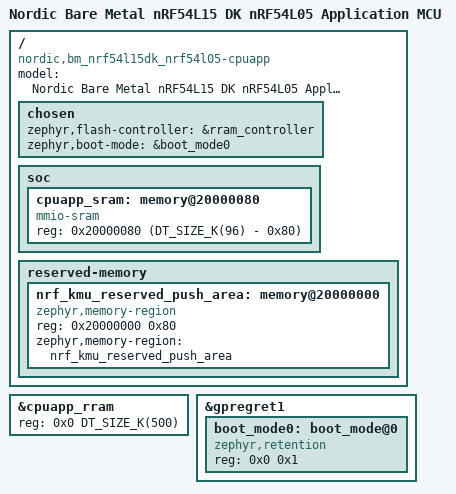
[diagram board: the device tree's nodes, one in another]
/*
 * Copyright (c) 2025 Nordic Semiconductor ASA
 *
 * SPDX-License-Identifier: LicenseRef-Nordic-5-Clause
 */

/* Override NCS default. */
#include "bm_nrf54l15dk_nrf54l051015_peripherals.dtsi"

#include "bm_nrf54l15dk_nrf54l051015_oscillator.dtsi"

/delete-node/ &cpuapp_sram;

/ {
	compatible = "nordic,bm_nrf54l15dk_nrf54l05-cpuapp";
	model = "Nordic Bare Metal nRF54L15 DK nRF54L05 Application MCU";

	chosen {
		zephyr,flash-controller = &rram_controller;
		zephyr,boot-mode = &boot_mode0;
	};

	soc {
		cpuapp_sram: memory@20000080 {
			compatible = "mmio-sram";
			#address-cells = <1>;
			#size-cells = <1>;
			reg = <0x20000080 (DT_SIZE_K(96) - 0x80)>;
			ranges = <0x0 0x20000080 (DT_SIZE_K(96) - 0x80)>;
		};
	};

	reserved-memory {
		#address-cells = <1>;
		#size-cells = <1>;
		ranges;

		nrf_kmu_reserved_push_area: memory@20000000 {
			compatible = "zephyr,memory-region", "mmio-sram";
			reg = <0x20000000 0x80>;
			zephyr,memory-region = "nrf_kmu_reserved_push_area";
		};
	};
};

/* Override NCS default to use entire RRAM for application CPU. */
&cpuapp_rram {
	reg = <0x0 DT_SIZE_K(500)>;
};

&gpregret1 {
	status = "okay";

	boot_mode0: boot_mode@0 {
		compatible = "zephyr,retention";
		status = "okay";
		reg = <0x0 0x1>;
	};
};
